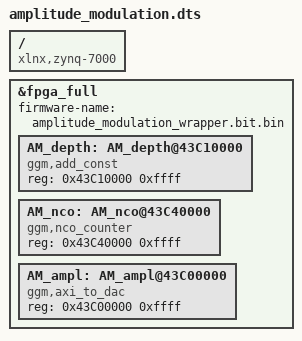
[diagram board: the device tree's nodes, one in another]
/dts-v1/;
/plugin/;

/ {
	compatible = "xlnx,zynq-7000";

	fragment0 {
		target = <&fpga_full>;
		#address-cells = <1>;
		#size-cells = <1>;
		__overlay__ {
			#address-cells = <1>;
			#size-cells = <1>;

			firmware-name = "amplitude_modulation_wrapper.bit.bin";

			AM_depth: AM_depth@43C10000{
				compatible = "ggm,add_const";
				reg = <0x43C10000 0xffff>;
			};

			AM_nco: AM_nco@43C40000{
				compatible = "ggm,nco_counter";
				reg = <0x43C40000 0xffff>;
			};

			AM_ampl: AM_ampl@43C00000{
				compatible = "ggm,axi_to_dac";
				reg = <0x43C00000 0xffff>;
			};

		};
	};
};
